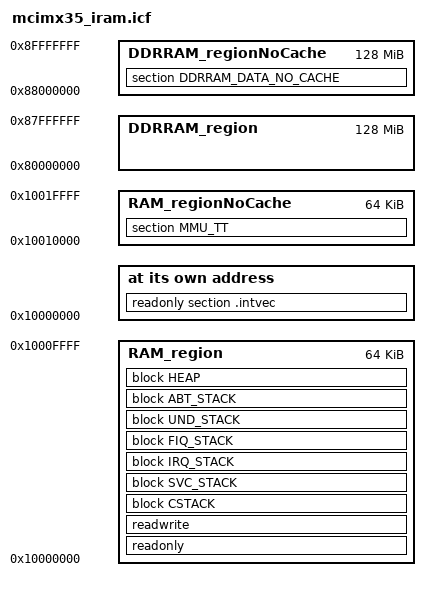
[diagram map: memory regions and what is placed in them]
/*###ICF### Section handled by ICF editor, don't touch! ****/
/*-Editor annotation file-*/
/* IcfEditorFile="$TOOLKIT_DIR$\config\ide\IcfEditor\a_v1_0.xml" */
/*-Specials-*/
define symbol __ICFEDIT_intvec_start__ = 0x10000000;
/*-Memory Regions-*/
define symbol __ICFEDIT_region_ROM_start__   = 0x0;
define symbol __ICFEDIT_region_ROM_end__     = 0x0;
define symbol __ICFEDIT_region_RAM_start__   = 0x10000000;
define symbol __ICFEDIT_region_RAM_end__     = 0x1000FFFF;
/*-Sizes-*/
define symbol __ICFEDIT_size_cstack__   = 0x100;
define symbol __ICFEDIT_size_svcstack__ = 0x40;
define symbol __ICFEDIT_size_irqstack__ = 0x40;
define symbol __ICFEDIT_size_fiqstack__ = 0x40;
define symbol __ICFEDIT_size_undstack__ = 0x40;
define symbol __ICFEDIT_size_abtstack__ = 0x40;
define symbol __ICFEDIT_size_heap__     = 0x0;
/**** End of ICF editor section. ###ICF###*/

define memory mem with size = 4G;

define symbol __region_RAM_no_cache_start__ = 0x10010000;
define symbol __region_RAM_no_cache_end__   = 0x1001FFFF;
define region RAM_region   = mem:[from __ICFEDIT_region_RAM_start__   to __ICFEDIT_region_RAM_end__];
define region RAM_regionNoCache = mem:[from __region_RAM_no_cache_start__ to __region_RAM_no_cache_end__];


define symbol __region_DDRRAM_start__ = 0x80000000;
define symbol __region_DDRRAM_end__   = 0x87FFFFFF;
define symbol __region_DDRRAM_no_cache_start__ = 0x88000000;
define symbol __region_DDRRAM_no_cache_end__   = 0x8FFFFFFF;
define region DDRRAM_region   = mem:[from __region_DDRRAM_start__   to __region_DDRRAM_end__];
define region DDRRAM_regionNoCache = mem:[from __region_DDRRAM_no_cache_start__ to __region_DDRRAM_no_cache_end__];

define block CSTACK    with alignment = 8, size = __ICFEDIT_size_cstack__   { };
define block SVC_STACK with alignment = 8, size = __ICFEDIT_size_svcstack__ { };
define block IRQ_STACK with alignment = 8, size = __ICFEDIT_size_irqstack__ { };
define block FIQ_STACK with alignment = 8, size = __ICFEDIT_size_fiqstack__ { };
define block UND_STACK with alignment = 8, size = __ICFEDIT_size_undstack__ { };
define block ABT_STACK with alignment = 8, size = __ICFEDIT_size_abtstack__ { };
define block HEAP      with alignment = 8, size = __ICFEDIT_size_heap__     { };

initialize by copy { readwrite };
do not initialize  { section .noinit };
do not initialize  { section MMU_TT };

place at address mem:__ICFEDIT_intvec_start__ { readonly section .intvec };

place in RAM_region   { readonly };
place in RAM_region   { readwrite,
                        block CSTACK, block SVC_STACK, block IRQ_STACK, block FIQ_STACK,
                        block UND_STACK, block ABT_STACK, block HEAP };

place in RAM_regionNoCache
                      { section MMU_TT};

place in DDRRAM_regionNoCache
                      { section DDRRAM_DATA_NO_CACHE };
